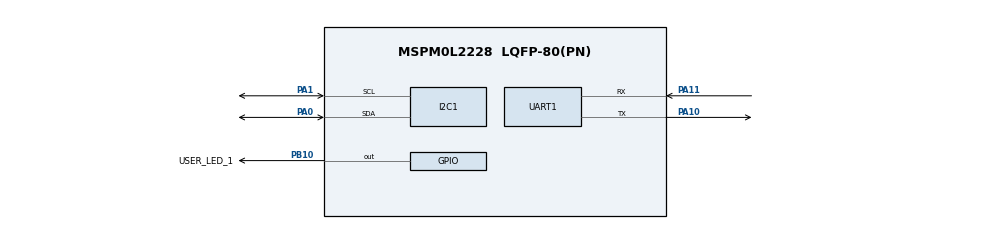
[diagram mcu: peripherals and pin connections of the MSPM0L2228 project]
//@cliArgs --device "MSPM0L222X" --package "LQFP-80(PN)" --part "Default"
//@v2CliArgs --device "MSPM0L2228" --package "LQFP-80(PN)"
// @cliArgs --board /ti/boards/LP_MSPM0L2228 --rtos nortos

/**
 * Import the modules used in this configuration.
 */
const GPIO          = scripting.addModule("/ti/driverlib/GPIO", {}, false);
const GPIO1         = GPIO.addInstance();
const I2C           = scripting.addModule("/ti/driverlib/I2C", {}, false);
const I2C1          = I2C.addInstance();
const SYSCTL        = scripting.addModule("/ti/driverlib/SYSCTL");
const UART          = scripting.addModule("/ti/driverlib/UART", {}, false);
const UART1         = UART.addInstance();
const ProjectConfig = scripting.addModule("/ti/project_config/ProjectConfig");

/**
 * Write custom configuration values to the imported modules.
 */
const mux8 = system.clockTree["LFXTMUX"];
scripting.suppress("Note: VBAT needs to be powered for LFCLK operation\\.", mux8, "inputSelect");

GPIO1.$name                          = "GPIO_LEDS";
GPIO1.associatedPins[0].$name        = "USER_LED_1";
GPIO1.associatedPins[0].assignedPort = "PORTB";
GPIO1.associatedPins[0].assignedPin  = "10";
GPIO1.associatedPins[0].pin.$assign  = "PB10";

const Board = scripting.addModule("/ti/driverlib/Board", {}, false);

I2C1.$name                             = "I2C";
I2C1.basicEnableTarget                 = true;
I2C1.advAnalogGlitchFilter             = "DISABLED";
I2C1.advTargetTXFIFOTRIG               = "BYTES_1";
I2C1.intTarget                         = ["ARBITRATION_LOST","INTERRUPT_OVERFLOW ","RXFIFO_OVERFLOW","RXFIFO_TRIGGER","START","STOP","TXFIFO_UNDERFLOW"];
I2C1.peripheral.$assign                = "I2C0";
I2C1.peripheral.sdaPin.$assign         = "PA0";
I2C1.peripheral.sclPin.$assign         = "PA1";

SYSCTL.clockTreeEn           = true;
SYSCTL.forceDefaultClkConfig = true;

UART1.targetBaudRate                   = 115200;
UART1.enabledInterrupts                = ["BREAK_ERROR","FRAMING_ERROR","NOISE_ERROR","OVERRUN_ERROR","PARITY_ERROR","RX","RX_TIMEOUT_ERROR","TX"];
UART1.$name                            = "UART";
UART1.peripheral.$assign               = "UART0";
UART1.peripheral.rxPin.$assign         = "PA11";
UART1.peripheral.txPin.$assign         = "PA10";

ProjectConfig.switchCondition = true;
scripting.suppress("Migrating requires going through the Switch Board or Device menu in the Device View section\\.", ProjectConfig, "deviceSpin");
